# STM32WL5X_CM0P register map
File version: 2.1
CPU: CM0 r0p1, little endian, MPU, no FPU, 4 interrupt priority bits
Registers are 32-bit, read-write, reset 0x0 unless marked. A register's access mark holds for its fields unless they carry their own. Offsets are from the block's base; [hi:lo] are bit positions; {n}, {i} and the like mark numbered series; 'fields as' and 'values as' point back to an identical list.

## AES — Advanced encryption standard hardware accelerator 1
Base 0x58001800
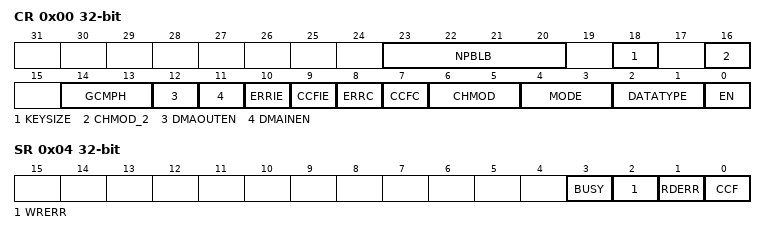
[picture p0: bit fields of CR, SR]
0x00 CR — control register
  [23:20] NPBLB — Number of padding bytes in last block of payload
  [18] KEYSIZE — Key size selection
    0=AES128 (128); 1=AES256 (256)
  [16] CHMOD_2 — AES chaining mode Bit2
    0=CHMOD (Mode as per CHMOD (ECB, CBC, CTR, GCM)); 1=CCM (Counter with CBC-MAC (CCM) - CHMOD must be 0 (ECB))
  [14:13] GCMPH — Used only for GCM, CCM and GMAC algorithms and has no effect when other algorithms are selected
    0=Init phase; 1=Header phase; 2=Payload phase; 3=Final Phase
  [12] DMAOUTEN — Enable DMA management of data output phase
    0=Disable DMA Output; 1=Enabled DMA Output
  [11] DMAINEN — Enable DMA management of data input phase
    0=Disable DMA Input; 1=Enable DMA Input
  [10] ERRIE — Error interrupt enable
    0=Disabled (Disable (mask) error interrupt); 1=Enabled (Enable error interrupt)
  [9] CCFIE — CCF flag interrupt enable
    0=Disabled (Disable (mask) CCF interrupt); 1=Enabled (Enable CCF interrupt)
  [8] ERRC — Error clear
    on write: 1=Clear RDERR and WRERR flags
  [7] CCFC — Computation Complete Flag Clear
    on write: 1=Clear computation complete flag
  [6:5] CHMOD — AES chaining mode Bit1 Bit0
    0=ECB (Electronic codebook (ECB) / Counter with CBC-MAC (CCM) if CHMOD2 is 1); 1=CBC (Cipher-block chaining (CBC)); 2=CTR (Counter mode (CTR)); 3=GCM (Galois counter mode (GCM) and Galois message authentication code (GMAC))
  [4:3] MODE — AES operating mode
    0=Mode 1: encryption; 1=Mode 2: key derivation (or key preparation for ECB/CBC decryption); 2=Mode 3: decryption; 3=Mode 4: key derivation then single decryption
  [2:1] DATATYPE — Data type selection (for data in and data out to/from the cryptographic block)
    0=None (Word); 1=Half-word (16-bit); 2=Byte (8-bit); 3=Bit
  [0] EN — AES enable
    0=Disabled (Disable AES); 1=Enabled (Enable AES)
0x04 SR ro — status register
  [3] BUSY — Busy flag
    0=Idle; 1=Busy
  [2] WRERR — Write error flag
    0=NoError (Write error not detected); 1=Error (Write error detected)
  [1] RDERR — Read error flag
    0=NoError (Read error not detected); 1=Error (Read error detected)
  [0] CCF — Computation complete flag
    0=Complete (Computation complete); 1=NotComplete (Computation not complete)
0x08 DINR — data input register
  [31:0] DIN — Data Input Register
0x0C DOUTR ro — data output register
  [31:0] DOUT — Data output register
0x10 KEYR0 wo — key register 0
  [31:0] KEY — Data Output Register (LSB key [31:0])
0x14 KEYR1 wo — key register 1
  [31:0] KEY — AES key register (key [63:32])
0x18 KEYR2 wo — key register 2
  [31:0] KEY — AES key register (key [95:64])
0x1C KEYR3 wo — key register 3
  [31:0] KEY — AES key register (MSB key [127:96])
0x20 IVR0 — initialization vector register 0
  [31:0] IVI — initialization vector register (LSB IVR [31:0])
0x24 IVR1 — initialization vector register 1
  [31:0] IVI — Initialization Vector Register (IVR [63:32])
0x28 IVR2 — initialization vector register 2
  [31:0] IVI — Initialization Vector Register (IVR [95:64])
0x2C IVR3 — initialization vector register 3
  [31:0] IVI — Initialization Vector Register (MSB IVR [127:96])
{0x20+4i} KEYR{i} wo (i=4..7) — key register {i}
  [31:0] KEY — AES key register (MSB key [{32i+31}:{32i}])
{0x40+4i} SUSP{i}R (i=0..7) — AES suspend register {i}
  [31:0] SUSP

## COMP — Comparator
Base 0x40010200
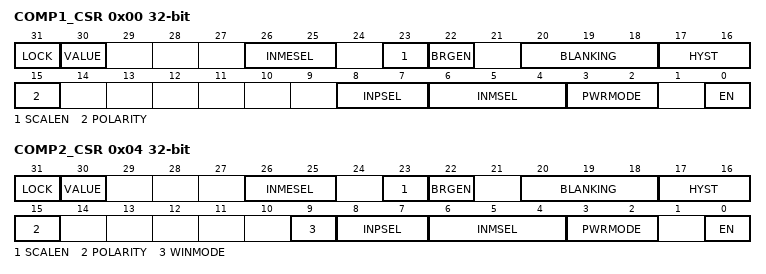
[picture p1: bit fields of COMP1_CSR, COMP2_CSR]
0x00 COMP1_CSR access per field
  [31] LOCK rw — COMP1_CSR register lock bit
    0=Unlocked (Comparator CSR bits are read-write); 1=Locked (Comparator CSR bits are read-only)
  [30] VALUE ro — Comparator 1 output status bit
    0=Low (Comparator output is low); 1=High (Comparator output is high)
  [26:25] INMESEL rw — comparator 1 input minus extended selection bits.
    0=PA10 (PA10 connected to input minus); 1=PA11 (PA11 connected to input minus); 2=PA15 (PA15 connected to input minus)
  [23] SCALEN rw — Voltage scaler enable bit
    0=Disabled (Voltage scaler disabled); 1=Enabled (Voltage scaler enabled)
  [22] BRGEN rw — Scaler bridge enable
    0=Disabled (Scaler resistor bridge disabled); 1=Enabled (Scaler resistor bridge enabled)
  [20:18] BLANKING rw — Comparator 1 blanking source selection bits
    0=NoBlanking; 1=TIM1OC5 (TIM1 OC5 selected as blanking source); 2=TIM2OC3 (TIM2 OC3 selected as blanking source)
  [17:16] HYST rw — Comparator 1 hysteresis selection bits
    0=None (No hysteresis); 1=Low (Low hysteresis); 2=Medium hysteresis; 3=High hysteresis
  [15] POLARITY rw — Comparator 1 polarity selection bit
    0=Normal (Comparator X output value not inverted); 1=Inverted (Comparator X output value inverted)
  [8:7] INPSEL rw — Comparator1 input plus selection bit
    0=PB4 (PB4 connected to input plus); 1=PB2 (PB2 connected to input plus)
  [6:4] INMSEL rw — Comparator 1 input minus selection bits
    0=OneQuarterVRef (1/4 of VRefint); 1=OneHalfVRef (1/2 of VRefint); 2=ThreeQuarterVRef (3/4 of VRefint); 3=VRefint; 4=DAC_CH1 (DAC Channel 1); 6=PB3; 7=GPIO (GPIO pin selected by INMESEL)
  [3:2] PWRMODE rw — Power Mode of the comparator 1
    0=High speed / full power; 1=Medium speed / medium power; 2=Low speed / low power; 3=Very-low speed / ultra-low power
  [0] EN rw — Comparator 1 enable bit
    0=Disabled (Comparator X disabled); 1=Enabled (Comparator X enabled)
0x04 COMP2_CSR access per field
  [31] LOCK rw — CSR register lock bit
    values as COMP1_CSR.LOCK
  [30] VALUE ro — Comparator 2 output status bit
    values as COMP1_CSR.VALUE
  [26:25] INMESEL rw — comparator 2 input minus extended selection bits.
    0=PB2 (PB2 connected to input minus); 1=PA10 (PA10 connected to input minus); 2=PA11 (PA11 connected to input minus)
  [23] SCALEN rw — Voltage scaler enable bit
    values as COMP1_CSR.SCALEN
  [22] BRGEN rw — Scaler bridge enable
    values as COMP1_CSR.BRGEN
  [20:18] BLANKING rw — Comparator 2 blanking source selection bits
    values as COMP1_CSR.BLANKING
  [17:16] HYST rw — Comparator 2 hysteresis selection bits
    values as COMP1_CSR.HYST
  [15] POLARITY rw — Comparator 2 polarity selection bit
    values as COMP1_CSR.POLARITY
  [9] WINMODE rw — Windows mode selection bit
    0=Disabled (COMP2 input plus is not connected to COMP1); 1=Enabled (COMP2 input plus is connected to COMP1)
  [8:7] INPSEL rw — Comparator 1 input plus selection bit
    0=PB4 (PB4 connected to input plus); 1=PB1 (PB1 connected to input plus); 2=PA15 (PA15 connected to input plus)
  [6:4] INMSEL rw — Comparator 2 input minus selection bits
    values as COMP1_CSR.INMSEL
  [3:2] PWRMODE rw — Power Mode of the comparator 2
    values as COMP1_CSR.PWRMODE
  [0] EN rw — Comparator 2 enable bit
    values as COMP1_CSR.EN
